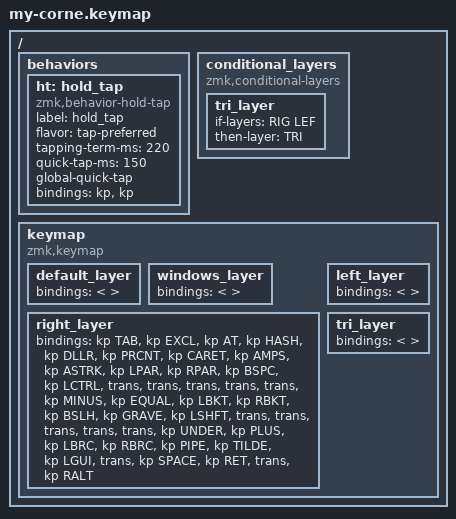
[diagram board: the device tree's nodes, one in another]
/*
 * Copyright (c) 2020 The ZMK Contributors
 *
 * SPDX-License-Identifier: MIT
 */

#include <behaviors.dtsi>
#include <dt-bindings/zmk/keys.h>
#include <dt-bindings/zmk/bt.h>

//home row mods
#define HRML(k2,k3,k4) &ht LALT k2  &ht LCTRL k3  &ht LGUI k4
#define HRMR(k1,k2,k3) &ht RGUI k1  &ht RCTRL k2  &ht RALT k3
#define WHRML(k2,k3,k4) &ht LALT k2  &ht LGUI k3  &ht LCTRL k4
#define WHRMR(k1,k2,k3) &ht RCTRL k1  &ht RGUI k2  &ht RALT k3

#define MAC 0
#define WIN 1
#define RIG 2
#define LEF 3
#define TRI 4

/ {
    behaviors {
        ht: hold_tap {
            label = "hold_tap";
            compatible = "zmk,behavior-hold-tap";
            #binding-cells = <2>;
            flavor = "tap-preferred";
            tapping-term-ms = <220>;
            quick-tap-ms = <150>;
            global-quick-tap;
            bindings = <&kp>, <&kp>;
        };
    };

    conditional_layers {
        compatible = "zmk,conditional-layers";
        tri_layer {
            if-layers = <RIG LEF>;
            then-layer = <TRI>;
        };
    };
        keymap {
                compatible = "zmk,keymap";

                default_layer {
                    bindings = <

//╭──────────┬──────────┬──────────┬──────────┬──────────┬──────────╮   ╭──────────┬──────────┬──────────┬──────────┬──────────┬──────────╮
//|    +     |  Q       |  W       |  E       |  R       |  T       |   |  Y       |    U     |  I       |  O       |   BSPC   |     |    |
//├──────────┼──────────┼──────────┼──────────┼──────────┼──────────┤   ├──────────┼──────────┼──────────┼──────────┼──────────┼──────────┤
//|    ESC   |  A       |  S       |  D       |  F       |  G       |   |  H       |  J       |  K       |  L       |    p     |     =    |
//├──────────┼──────────┼──────────┼──────────┼──────────┼──────────┤   ├──────────┼──────────┼──────────┼──────────┼──────────┼──────────┤
//|     -    |  Z       |  X       |  C       |  V       |  B       |   |  N       |  M       |  ,       |  .       |    ent   |     _    |   
//╰──────────┴──────────┴──────────┼──────────┼──────────┼──────────┤   ├──────────┼──────────┼──────────┼──────────┴──────────┴──────────╯
//                                 | GUI      | LWR  Tab | BSPC     |   | SPC      | RSE  Ent | ALT      |
//                                 ╰──────────┴──────────┴──────────╯   ╰──────────┴──────────┴──────────╯
                        >;
                };
                
                windows_layer {
                    bindings = <
                    
//╭──────────┬──────────┬──────────┬──────────┬──────────┬──────────╮   ╭──────────┬──────────┬──────────┬──────────┬──────────┬──────────╮
//|    +     |  Q       |  W       |  E       |  R       |  T       |   |  Y       |    U     |  I       |  O       |   BSPC   |     |    |
//├──────────┼──────────┼──────────┼──────────┼──────────┼──────────┤   ├──────────┼──────────┼──────────┼──────────┼──────────┼──────────┤
//|    ESC   |  A       |  S       |  D       |  F       |  G       |   |  H       |  J       |  K       |  L       |    p     |     =    |
//├──────────┼──────────┼──────────┼──────────┼──────────┼──────────┤   ├──────────┼──────────┼──────────┼──────────┼──────────┼──────────┤
//|     -    |  Z       |  X       |  C       |  V       |  B       |   |  N       |  M       |  ,       |  .       |    ent   |     _    |   
//╰──────────┴──────────┴──────────┼──────────┼──────────┼──────────┤   ├──────────┼──────────┼──────────┼──────────┴──────────┴──────────╯
//                                 | GUI      | LWR  Tab | BSPC     |   | SPC      | RSE  Ent | ALT      |
//                                 ╰──────────┴──────────┴──────────╯   ╰──────────┴──────────┴──────────╯
                        >;
                };


                right_layer {
                    bindings = <
                        
//╭──────────┬──────────┬──────────┬──────────┬──────────┬──────────╮   ╭──────────┬──────────┬──────────┬──────────┬──────────┬──────────╮
//|          |     1    |     2    |     3    |     4    |     5    |   |     6    |     7    |     8    |     9    |     0    |          |
//├──────────┼──────────┼──────────┼──────────┼──────────┼──────────┤   ├──────────┼──────────┼──────────┼──────────┼──────────┼──────────┤
//|          |    del   |   caps   |   print  |   inst   |          |   |          |   left   |   down   |    up    |   right  |          |
//├──────────┼──────────┼──────────┼──────────┼──────────┼──────────┤   ├──────────┼──────────┼──────────┼──────────┼──────────┼──────────┤
//|          |          |          |          |          |          |   |          |   home   |   pg dw  |   pg up  |    end   |          |
//╰──────────┴──────────┴──────────┼──────────┼──────────┼──────────┤   ├──────────┼──────────┼──────────┼──────────┴──────────┴──────────╯
//                                 |          |          |          |   |          |          |          |
//                                 ╰──────────┴──────────┴──────────╯   ╰──────────┴──────────┴──────────╯
   &kp  TAB  &kp EXCL &kp AT &kp HASH &kp DLLR &kp PRCNT   &kp CARET &kp AMPS  &kp ASTRK &kp LPAR &kp RPAR &kp BSPC
   &kp LCTRL &trans   &trans &trans   &trans   &trans      &kp MINUS &kp EQUAL &kp LBKT  &kp RBKT &kp BSLH &kp GRAVE
   &kp LSHFT &trans   &trans &trans   &trans   &trans      &kp UNDER &kp PLUS  &kp LBRC  &kp RBRC &kp PIPE &kp TILDE
                             &kp LGUI &trans   &kp SPACE   &kp RET   &trans    &kp RALT
                        >;
                };
                left_layer{
                    bindings = <
                    
//╭──────────┬──────────┬──────────┬──────────┬──────────┬──────────╮   ╭──────────┬──────────┬──────────┬──────────┬──────────┬──────────╮
//|          |     !    |     @    |     #    |     $    |     %    |   |     ^    |     &    |     *    |     `    |     ~    |          |
//├──────────┼──────────┼──────────┼──────────┼──────────┼──────────┤   ├──────────┼──────────┼──────────┼──────────┼──────────┼──────────┤
//|          |     "    |     [    |     {    |    (     |     <    |   |     /    |     -    |     =    |     :    |     ;    |          |
//├──────────┼──────────┼──────────┼──────────┼──────────┼──────────┤   ├──────────┼──────────┼──────────┼──────────┼──────────┼──────────┤
//|          |     '    |     ]    |     }    |    )     |     >    |   |     \    |     _    |     +    |     |    |     ?    |          |
//╰──────────┴──────────┴──────────┼──────────┼──────────┼──────────┤   ├──────────┼──────────┼──────────┼──────────┴──────────┴──────────╯
//                                 |          |          |          |   |          |          |          |
//                                 ╰──────────┴──────────┴──────────╯   ╰──────────┴──────────┴──────────╯

                    >;
                };
                tri_layer{
                    bindings = <
        
//╭──────────┬──────────┬──────────┬──────────┬──────────┬──────────╮   ╭──────────┬──────────┬──────────┬──────────┬──────────┬──────────╮
//|          |    f1    |    f2    |    f3    |    f4    |   pro_0  |   |   pro_2  |  tg out  |    win   |   mute   |   next   |          |
//├──────────┼──────────┼──────────┼──────────┼──────────┼──────────┤   ├──────────┼──────────┼──────────┼──────────┼──────────┼──────────┤
//|          |    f5    |    f6    |    f7    |    f8    |   pro_1  |   |   pro_3  |  inc brt |   game   |  vol up  |   pause  |          |
//├──────────┼──────────┼──────────┼──────────┼──────────┼──────────┤   ├──────────┼──────────┼──────────┼──────────┼──────────┼──────────┤
//|          |    f9    |    f10   |   f11    |   f12    |  BT_CLR  |   |   pro_4  |  dec brt |          |  vol dn  |   prev   |          |
//╰──────────┴──────────┴──────────┼──────────┼──────────┼──────────┤   ├──────────┼──────────┼──────────┼──────────┴──────────┴──────────╯
//                                 |          |          |          |   |          |          |          |
//                                 ╰──────────┴──────────┴──────────╯   ╰──────────┴──────────┴──────────╯
                    >;
                };
        };
};
